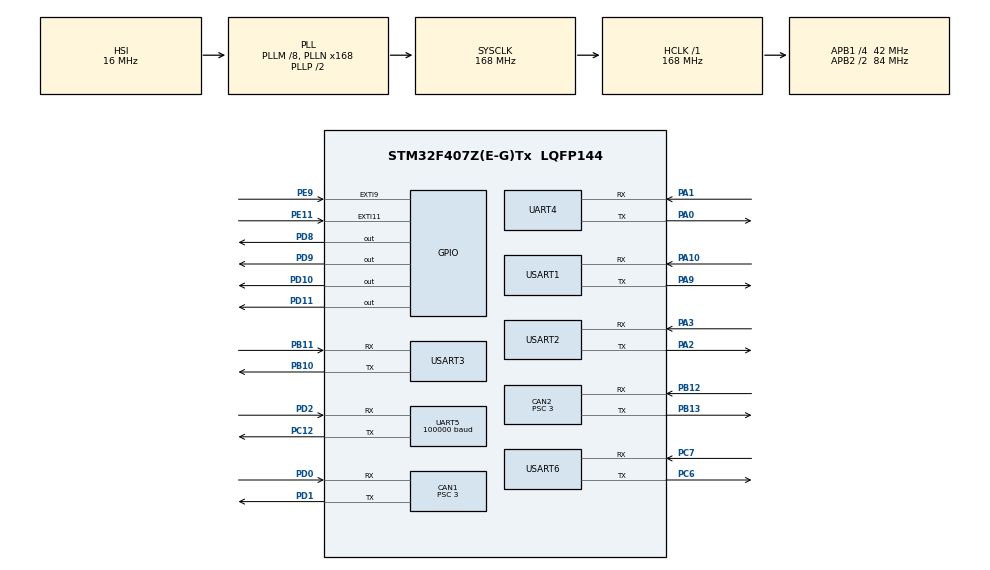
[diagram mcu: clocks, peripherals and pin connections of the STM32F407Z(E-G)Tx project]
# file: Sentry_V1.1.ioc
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CAN1.BS1=CAN_BS1_10TQ
CAN1.BS2=CAN_BS2_3TQ
CAN1.CalculateBaudRate=1000000
CAN1.CalculateTimeBit=1000
CAN1.CalculateTimeQuantum=71.42857142857143
CAN1.Prescaler=3
CAN2.BS1=CAN_BS1_10TQ
CAN2.BS2=CAN_BS2_3TQ
CAN2.CalculateBaudRate=1000000
CAN2.CalculateTimeBit=1000
CAN2.CalculateTimeQuantum=71.42857142857143
CAN2.Prescaler=3
Dma.Request0=UART5_RX
Dma.Request1=USART6_RX
Dma.Request2=USART6_TX
Dma.Request3=USART3_TX
Dma.UART5_RX.0.Direction=DMA_PERIPH_TO_MEMORY
Dma.UART5_RX.0.FIFOMode=DMA_FIFOMODE_DISABLE
Dma.UART5_RX.0.Instance=DMA1_Stream0
Dma.UART5_RX.0.MemDataAlignment=DMA_MDATAALIGN_BYTE
Dma.UART5_RX.0.MemInc=DMA_MINC_ENABLE
Dma.UART5_RX.0.Mode=DMA_NORMAL
Dma.UART5_RX.0.PeriphDataAlignment=DMA_PDATAALIGN_BYTE
Dma.UART5_RX.0.PeriphInc=DMA_PINC_DISABLE
Dma.UART5_RX.0.Priority=DMA_PRIORITY_MEDIUM
Dma.USART3_TX.3.Direction=DMA_MEMORY_TO_PERIPH
Dma.USART3_TX.3.FIFOMode=DMA_FIFOMODE_DISABLE
Dma.USART3_TX.3.Instance=DMA1_Stream3
Dma.USART3_TX.3.MemDataAlignment=DMA_MDATAALIGN_BYTE
Dma.USART3_TX.3.MemInc=DMA_MINC_ENABLE
Dma.USART3_TX.3.Mode=DMA_NORMAL
Dma.USART3_TX.3.PeriphDataAlignment=DMA_PDATAALIGN_BYTE
Dma.USART3_TX.3.PeriphInc=DMA_PINC_DISABLE
Dma.USART3_TX.3.Priority=DMA_PRIORITY_LOW
Dma.USART6_RX.1.Direction=DMA_PERIPH_TO_MEMORY
Dma.USART6_RX.1.FIFOMode=DMA_FIFOMODE_DISABLE
Dma.USART6_RX.1.Instance=DMA2_Stream1
Dma.USART6_RX.1.MemDataAlignment=DMA_MDATAALIGN_BYTE
Dma.USART6_RX.1.MemInc=DMA_MINC_ENABLE
Dma.USART6_RX.1.Mode=DMA_NORMAL
Dma.USART6_RX.1.PeriphDataAlignment=DMA_PDATAALIGN_BYTE
Dma.USART6_RX.1.PeriphInc=DMA_PINC_DISABLE
Dma.USART6_RX.1.Priority=DMA_PRIORITY_LOW
Dma.USART6_TX.2.Direction=DMA_MEMORY_TO_PERIPH
Dma.USART6_TX.2.FIFOMode=DMA_FIFOMODE_DISABLE
Dma.USART6_TX.2.Instance=DMA2_Stream6
Dma.USART6_TX.2.MemDataAlignment=DMA_MDATAALIGN_BYTE
Dma.USART6_TX.2.MemInc=DMA_MINC_ENABLE
Dma.USART6_TX.2.Mode=DMA_NORMAL
Dma.USART6_TX.2.PeriphDataAlignment=DMA_PDATAALIGN_BYTE
Dma.USART6_TX.2.PeriphInc=DMA_PINC_DISABLE
Dma.USART6_TX.2.Priority=DMA_PRIORITY_LOW
FREERTOS.Tasks01=Power_Control,0,512,Power_Control_Task_Start,As weak,NULL,Dynamic,NULL,NULL;Chassis_Task,0,1024,Chassis_Task_Start,As weak,NULL,Dynamic,NULL,NULL;Data_Tx_Task,1,512,Data_Tx_Task_Start,As weak,NULL,Dynamic,NULL,NULL;Debug_Task,-3,128,Debug_Task_Start,As weak,NULL,Dynamic,NULL,NULL;Referee_Task,-1,512,Referee_Task_Start,As weak,NULL,Dynamic,NULL,NULL
Mcu.Family=STM32F4
Mcu.Name=STM32F407Z(E-G)Tx
Mcu.Package=LQFP144
NVIC.CAN1_RX0_IRQn=true\:5\:0\:false\:false\:true\:true\:true\:true
NVIC.CAN2_RX1_IRQn=true\:5\:0\:false\:false\:true\:true\:true\:true
NVIC.DMA1_Stream0_IRQn=true\:5\:0\:false\:false\:true\:true\:false\:true
NVIC.DMA1_Stream3_IRQn=true\:5\:0\:false\:false\:true\:true\:false\:true
NVIC.DMA2_Stream1_IRQn=true\:5\:0\:false\:false\:true\:true\:false\:true
NVIC.DMA2_Stream6_IRQn=true\:5\:0\:false\:false\:true\:true\:false\:true
NVIC.EXTI15_10_IRQn=true\:5\:0\:false\:false\:true\:false\:true\:true
NVIC.EXTI9_5_IRQn=true\:5\:0\:false\:false\:true\:true\:true\:true
NVIC.PriorityGroup=NVIC_PRIORITYGROUP_4
NVIC.TIM1_UP_TIM10_IRQn=true\:15\:0\:false\:false\:true\:false\:false\:true
NVIC.TIM8_TRG_COM_TIM14_IRQn=true\:5\:0\:false\:false\:true\:true\:true\:true
NVIC.TIM8_UP_TIM13_IRQn=true\:5\:0\:false\:false\:true\:true\:true\:true
NVIC.TimeBase=TIM1_UP_TIM10_IRQn
NVIC.TimeBaseIP=TIM1
NVIC.UART5_IRQn=true\:4\:0\:true\:false\:true\:false\:true\:true
NVIC.USART3_IRQn=true\:5\:0\:false\:false\:true\:true\:true\:true
NVIC.USART6_IRQn=true\:5\:0\:false\:false\:true\:true\:true\:true
PA0-WKUP.Mode=Asynchronous
PA0-WKUP.Signal=UART4_TX
PA1.Mode=Asynchronous
PA1.Signal=UART4_RX
PA10.Mode=Asynchronous
PA10.Signal=USART1_RX
PA13.Mode=Serial_Wire
PA13.Signal=SYS_JTMS-SWDIO
PA14.Mode=Serial_Wire
PA14.Signal=SYS_JTCK-SWCLK
PA2.Mode=Asynchronous
PA2.Signal=USART2_TX
PA3.Mode=Asynchronous
PA3.Signal=USART2_RX
PA9.Mode=Asynchronous
PA9.Signal=USART1_TX
PB10.Mode=Asynchronous
PB10.Signal=USART3_TX
PB11.Mode=Asynchronous
PB11.Signal=USART3_RX
PB12.Mode=CAN_Activate
PB12.Signal=CAN2_RX
PB13.Mode=CAN_Activate
PB13.Signal=CAN2_TX
PC12.Mode=Asynchronous
PC12.Signal=UART5_TX
PC6.GPIO_Speed=GPIO_SPEED_FREQ_VERY_HIGH
PC6.Mode=Asynchronous
PC6.Signal=USART6_TX
PC7.GPIO_Speed=GPIO_SPEED_FREQ_VERY_HIGH
PC7.Mode=Asynchronous
PC7.Signal=USART6_RX
PD0.Mode=CAN_Activate
PD0.Signal=CAN1_RX
PD1.Mode=CAN_Activate
PD1.Signal=CAN1_TX
PD10.Signal=GPIO_Output
PD11.Signal=GPIO_Output
PD2.Mode=Asynchronous
PD2.Signal=UART5_RX
PD8.Signal=GPIO_Output
PD9.Signal=GPIO_Output
PE11.GPIO_ModeDefaultEXTI=GPIO_MODE_IT_FALLING
PE11.GPIO_PuPd=GPIO_PULLDOWN
PE11.Signal=GPXTI11
PE9.GPIO_ModeDefaultEXTI=GPIO_MODE_IT_FALLING
PE9.GPIO_PuPd=GPIO_PULLDOWN
PE9.Signal=GPXTI9
PH0-OSC_IN.Mode=HSE-External-Oscillator
PH0-OSC_IN.Signal=RCC_OSC_IN
PH1-OSC_OUT.Mode=HSE-External-Oscillator
PH1-OSC_OUT.Signal=RCC_OSC_OUT
ProjectManager.HeapSize=0x2000
ProjectManager.StackSize=0x4000
ProjectManager.TargetToolchain=MDK-ARM V5.32
RCC.48MHZClocksFreq_Value=84000000
RCC.AHBFreq_Value=168000000
RCC.APB1CLKDivider=RCC_HCLK_DIV4
RCC.APB1Freq_Value=42000000
RCC.APB1TimFreq_Value=84000000
RCC.APB2CLKDivider=RCC_HCLK_DIV2
RCC.APB2Freq_Value=84000000
RCC.APB2TimFreq_Value=168000000
RCC.CortexFreq_Value=168000000
RCC.HCLKFreq_Value=168000000
RCC.HSE_VALUE=25000000
RCC.HSI_VALUE=16000000
RCC.LSE_VALUE=32768
RCC.PLLM=8
RCC.PLLN=168
RCC.SYSCLKFreq_VALUE=168000000
RCC.SYSCLKSource=RCC_SYSCLKSOURCE_PLLCLK
RCC.VCOOutputFreq_Value=336000000
TIM13.Period=9999
TIM13.Prescaler=83
TIM14.Period=999
TIM14.Prescaler=83
UART4.VirtualMode=Asynchronous
UART5.BaudRate=100000
UART5.Mode=MODE_TX_RX
UART5.Parity=PARITY_NONE
UART5.VirtualMode=Asynchronous
USART1.VirtualMode=VM_ASYNC
USART2.VirtualMode=VM_ASYNC
USART3.VirtualMode=VM_ASYNC
USART6.VirtualMode=VM_ASYNC
VP_FREERTOS_VS_CMSIS_V1.Mode=CMSIS_V1
VP_SYS_VS_tim1.Mode=TIM1
VP_TIM13_VS_ClockSourceINT.Mode=Enable_Timer
VP_TIM14_VS_ClockSourceINT.Mode=Enable_Timer
board=custom

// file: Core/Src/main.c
/* USER CODE BEGIN Header */
/**
  ******************************************************************************
  * @file           : main.c
  * @brief          : Main program body
  ******************************************************************************
  * @attention
  *
  * Copyright (c) 2022 STMicroelectronics.
  * All rights reserved.
  *
  * This software is licensed under terms that can be found in the LICENSE file
  * in the root directory of this software component.
  * If no LICENSE file comes with this software, it is provided AS-IS.
  *
  ******************************************************************************
  */
/* USER CODE END Header */
#include "main.h"
#include "cmsis_os.h"
#include "can.h"
#include "dma.h"
#include "tim.h"
#include "usart.h"
#include "gpio.h"

/* USER CODE BEGIN Includes */
#include "bsp_motor.h"
#include "bsp_timer.h"
#include "bsp_rc.h"
#include "fuzzyPID.h"
/* USER CODE END Includes */

/* USER CODE BEGIN PV */
const motor_measure_t *motor;
/* USER CODE END PV */

void SystemClock_Config(void);
void MX_FREERTOS_Init(void);

int main(void)
{

  /* MCU Configuration--------------------------------------------------------*/

  /* Reset of all peripherals, Initializes the Flash interface and the Systick. */
  HAL_Init();

  /* Configure the system clock */
  SystemClock_Config();

  /* Initialize all configured peripherals */
  MX_GPIO_Init();
  MX_DMA_Init();
  MX_CAN1_Init();
  MX_CAN2_Init();
  MX_UART4_Init();
  MX_UART5_Init();
  MX_USART1_UART_Init();
  MX_USART2_UART_Init();
  MX_USART3_UART_Init();
  MX_USART6_UART_Init();
  MX_TIM13_Init();
  MX_TIM14_Init();
  /* USER CODE BEGIN 2 */
	remote_init();
	can_filter_init();
	Timer_Start();
  /* USER CODE END 2 */

  /* Call init function for freertos objects (in freertos.c) */
  MX_FREERTOS_Init();
  /* Start scheduler */
  osKernelStart();

  /* We should never get here as control is now taken by the scheduler */
  /* Infinite loop */
  while (1)
  {

    /* USER CODE BEGIN 3 */
//		CAN1_CMD(500,0,0,0,0,0,0,0);
//		motor = get_can1_motor_measure_point(0);
//		FuzzyPIDcontroller();

  }
  /* USER CODE END 3 */
}

void SystemClock_Config(void)
{
  RCC_OscInitTypeDef RCC_OscInitStruct = {0};
  RCC_ClkInitTypeDef RCC_ClkInitStruct = {0};

  /** Configure the main internal regulator output voltage
  */
  __HAL_RCC_PWR_CLK_ENABLE();
  __HAL_PWR_VOLTAGESCALING_CONFIG(PWR_REGULATOR_VOLTAGE_SCALE1);
  /** Initializes the RCC Oscillators according to the specified parameters
  * in the RCC_OscInitTypeDef structure.
  */
  RCC_OscInitStruct.OscillatorType = RCC_OSCILLATORTYPE_HSI;
  RCC_OscInitStruct.HSIState = RCC_HSI_ON;
  RCC_OscInitStruct.HSICalibrationValue = RCC_HSICALIBRATION_DEFAULT;
  RCC_OscInitStruct.PLL.PLLState = RCC_PLL_ON;
  RCC_OscInitStruct.PLL.PLLSource = RCC_PLLSOURCE_HSI;
  RCC_OscInitStruct.PLL.PLLM = 8;
  RCC_OscInitStruct.PLL.PLLN = 168;
  RCC_OscInitStruct.PLL.PLLP = RCC_PLLP_DIV2;
  RCC_OscInitStruct.PLL.PLLQ = 4;
  if (HAL_RCC_OscConfig(&RCC_OscInitStruct) != HAL_OK)
  {
    Error_Handler();
  }
  /** Initializes the CPU, AHB and APB buses clocks
  */
  RCC_ClkInitStruct.ClockType = RCC_CLOCKTYPE_HCLK|RCC_CLOCKTYPE_SYSCLK
                              |RCC_CLOCKTYPE_PCLK1|RCC_CLOCKTYPE_PCLK2;
  RCC_ClkInitStruct.SYSCLKSource = RCC_SYSCLKSOURCE_PLLCLK;
  RCC_ClkInitStruct.AHBCLKDivider = RCC_SYSCLK_DIV1;
  RCC_ClkInitStruct.APB1CLKDivider = RCC_HCLK_DIV4;
  RCC_ClkInitStruct.APB2CLKDivider = RCC_HCLK_DIV2;

  if (HAL_RCC_ClockConfig(&RCC_ClkInitStruct, FLASH_LATENCY_5) != HAL_OK)
  {
    Error_Handler();
  }
}

void Error_Handler(void)
{
  __disable_irq();
  while (1)
  {
  }
}

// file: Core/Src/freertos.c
/* USER CODE BEGIN Header */
/**
  ******************************************************************************
  * File Name          : freertos.c
  * Description        : Code for freertos applications
  ******************************************************************************
  * @attention
  *
  * Copyright (c) 2022 STMicroelectronics.
  * All rights reserved.
  *
  * This software is licensed under terms that can be found in the LICENSE file
  * in the root directory of this software component.
  * If no LICENSE file comes with this software, it is provided AS-IS.
  *
  ******************************************************************************
  */
/* USER CODE END Header */

#include "FreeRTOS.h"
#include "task.h"
#include "main.h"
#include "cmsis_os.h"

osThreadId Power_ControlHandle;
osThreadId Chassis_TaskHandle;
osThreadId Data_Tx_TaskHandle;
osThreadId Debug_TaskHandle;
osThreadId Referee_TaskHandle;

void Power_Control_Task_Start(void const * argument);
void Chassis_Task_Start(void const * argument);
void Data_Tx_Task_Start(void const * argument);
void Debug_Task_Start(void const * argument);
void Referee_Task_Start(void const * argument);

void MX_FREERTOS_Init(void); /* (MISRA C 2004 rule 8.1) */

/* GetIdleTaskMemory prototype (linked to static allocation support) */
void vApplicationGetIdleTaskMemory( StaticTask_t **ppxIdleTaskTCBBuffer, StackType_t **ppxIdleTaskStackBuffer, uint32_t *pulIdleTaskStackSize );

/* USER CODE BEGIN GET_IDLE_TASK_MEMORY */
static StaticTask_t xIdleTaskTCBBuffer;
static StackType_t xIdleStack[configMINIMAL_STACK_SIZE];

void vApplicationGetIdleTaskMemory( StaticTask_t **ppxIdleTaskTCBBuffer, StackType_t **ppxIdleTaskStackBuffer, uint32_t *pulIdleTaskStackSize )
{
  *ppxIdleTaskTCBBuffer = &xIdleTaskTCBBuffer;
  *ppxIdleTaskStackBuffer = &xIdleStack[0];
  *pulIdleTaskStackSize = configMINIMAL_STACK_SIZE;
  /* place for user code */
}
/* USER CODE END GET_IDLE_TASK_MEMORY */

void MX_FREERTOS_Init(void) {

  /* Create the thread(s) */
  /* definition and creation of Power_Control */
  osThreadDef(Power_Control, Power_Control_Task_Start, osPriorityNormal, 0, 512);
  Power_ControlHandle = osThreadCreate(osThread(Power_Control), NULL);

  /* definition and creation of Chassis_Task */
  osThreadDef(Chassis_Task, Chassis_Task_Start, osPriorityNormal, 0, 1024);
  Chassis_TaskHandle = osThreadCreate(osThread(Chassis_Task), NULL);

  /* definition and creation of Data_Tx_Task */
  osThreadDef(Data_Tx_Task, Data_Tx_Task_Start, osPriorityAboveNormal, 0, 512);
  Data_Tx_TaskHandle = osThreadCreate(osThread(Data_Tx_Task), NULL);

  /* definition and creation of Debug_Task */
  osThreadDef(Debug_Task, Debug_Task_Start, osPriorityIdle, 0, 128);
  Debug_TaskHandle = osThreadCreate(osThread(Debug_Task), NULL);

  /* definition and creation of Referee_Task */
  osThreadDef(Referee_Task, Referee_Task_Start, osPriorityBelowNormal, 0, 512);
  Referee_TaskHandle = osThreadCreate(osThread(Referee_Task), NULL);

}

__weak void Power_Control_Task_Start(void const * argument)
{
  for(;;)
  {
    osDelay(1);
  }
}

__weak void Chassis_Task_Start(void const * argument)
{
  for(;;)
  {
    osDelay(1);
  }
}

__weak void Data_Tx_Task_Start(void const * argument)
{
  for(;;)
  {
    osDelay(1);
  }
}

__weak void Debug_Task_Start(void const * argument)
{
  for(;;)
  {
    osDelay(1);
  }
}

__weak void Referee_Task_Start(void const * argument)
{
  for(;;)
  {
    osDelay(1);
  }
}
